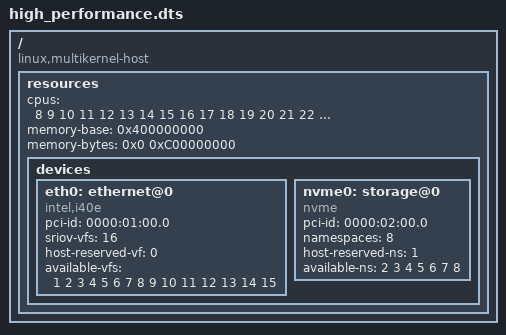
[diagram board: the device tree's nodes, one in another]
/*
 * High Performance Baseline Example
 *
 * Baseline defines large-scale hardware resources (128 CPUs, 64GB).
 * Usage: kerf init --input=high_performance.dts --apply
 */

/multikernel-v1/;

/ {
    compatible = "linux,multikernel-host";

    resources {
        cpus = <8 9 10 11 12 13 14 15 16 17 18 19 20 21 22 23 
                24 25 26 27 28 29 30 31 32 33 34 35 36 37 38 39
                40 41 42 43 44 45 46 47 48 49 50 51 52 53 54 55
                56 57 58 59 60 61 62 63 64 65 66 67 68 69 70 71
                72 73 74 75 76 77 78 79 80 81 82 83 84 85 86 87
                88 89 90 91 92 93 94 95 96 97 98 99 100 101 102 103
                104 105 106 107 108 109 110 111 112 113 114 115 116 117 118 119>;
        memory-base = <0x400000000>;
        memory-bytes = <0x0 0xC00000000>;   // 48GB
        
        devices {
            eth0: ethernet@0 {
                compatible = "intel,i40e";
                pci-id = "0000:01:00.0";
                sriov-vfs = <16>;
                host-reserved-vf = <0>;
                available-vfs = <1 2 3 4 5 6 7 8 9 10 11 12 13 14 15>;
            };
            
            nvme0: storage@0 {
                compatible = "nvme";
                pci-id = "0000:02:00.0";
                namespaces = <8>;
                host-reserved-ns = <1>;
                available-ns = <2 3 4 5 6 7 8>;
            };
        };
    };
};
